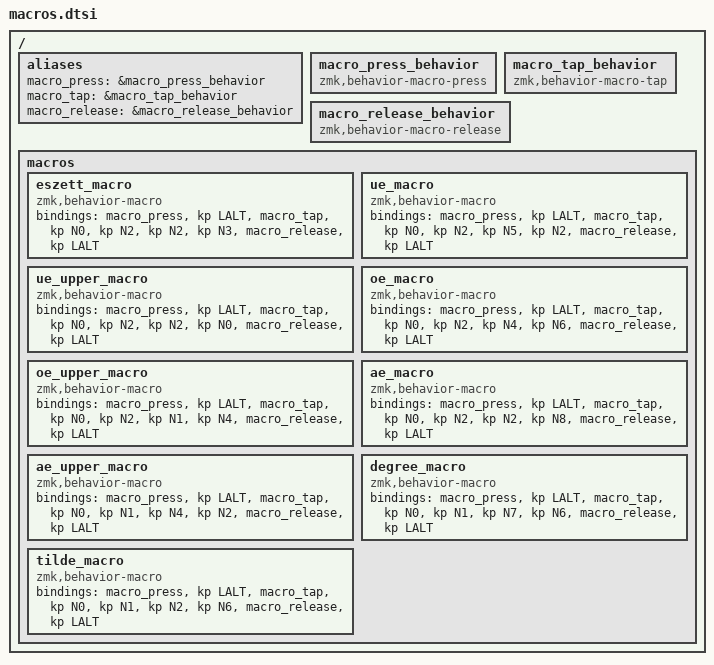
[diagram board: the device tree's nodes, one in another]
/ {
    aliases {
        macro_press = &macro_press_behavior;
        macro_tap = &macro_tap_behavior;
        macro_release = &macro_release_behavior;
    };

    macro_press_behavior: macro_press_behavior {
        compatible = "zmk,behavior-macro-press";
    };

    macro_tap_behavior: macro_tap_behavior {
        compatible = "zmk,behavior-macro-tap";
    };

    macro_release_behavior: macro_release_behavior {
        compatible = "zmk,behavior-macro-release";
    };

    macros {
        eszett_macro: eszett_macro {
            compatible = "zmk,behavior-macro";
            #binding-cells = <0>;
            bindings = <
                &macro_press   &kp LALT
                &macro_tap     &kp N0 &kp N2 &kp N2 &kp N3
                &macro_release &kp LALT
            >;
        };

        ue_macro: ue_macro {
            compatible = "zmk,behavior-macro";
            #binding-cells = <0>;
            bindings = <
                &macro_press   &kp LALT
                &macro_tap     &kp N0 &kp N2 &kp N5 &kp N2
                &macro_release &kp LALT
            >;
        };

        ue_upper_macro: ue_upper_macro {
            compatible = "zmk,behavior-macro";
            #binding-cells = <0>;
            bindings = <
                &macro_press   &kp LALT
                &macro_tap     &kp N0 &kp N2 &kp N2 &kp N0
                &macro_release &kp LALT
            >;
        };

        oe_macro: oe_macro {
            compatible = "zmk,behavior-macro";
            #binding-cells = <0>;
            bindings = <
                &macro_press   &kp LALT
                &macro_tap     &kp N0 &kp N2 &kp N4 &kp N6
                &macro_release &kp LALT
            >;
        };

        oe_upper_macro: oe_upper_macro {
            compatible = "zmk,behavior-macro";
            #binding-cells = <0>;
            bindings = <
                &macro_press   &kp LALT
                &macro_tap     &kp N0 &kp N2 &kp N1 &kp N4
                &macro_release &kp LALT
            >;
        };

        ae_macro: ae_macro {
            compatible = "zmk,behavior-macro";
            #binding-cells = <0>;
            bindings = <
                &macro_press   &kp LALT
                &macro_tap     &kp N0 &kp N2 &kp N2 &kp N8
                &macro_release &kp LALT
            >;
        };

        ae_upper_macro: ae_upper_macro {
            compatible = "zmk,behavior-macro";
            #binding-cells = <0>;
            bindings = <
                &macro_press   &kp LALT
                &macro_tap     &kp N0 &kp N1 &kp N4 &kp N2
                &macro_release &kp LALT
            >;
        };

        degree_macro: degree_macro {
            compatible = "zmk,behavior-macro";
            #binding-cells = <0>;
            bindings = <
                &macro_press   &kp LALT
                &macro_tap     &kp N0 &kp N1 &kp N7 &kp N6
                &macro_release &kp LALT
            >;
        };

        tilde_macro: tilde_macro {
            compatible = "zmk,behavior-macro";
            #binding-cells = <0>;
            bindings = <
                &macro_press   &kp LALT
                &macro_tap     &kp N0 &kp N1 &kp N2 &kp N6
                &macro_release &kp LALT
            >;
        };
    };
};
